# SIM3L164_C register map
File version: 1
CPU: 
Registers are 32-bit, read-write, reset 0x0 unless marked. A register's access mark holds for its fields unless they carry their own. Offsets are from the block's base; [hi:lo] are bit positions; {n}, {i} and the like mark numbered series.

## EXTOSC_0
Base 0x4003C000
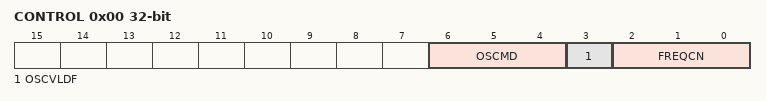
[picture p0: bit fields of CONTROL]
0x00 CONTROL — Oscillator Control
  [6:4] OSCMD — Oscillator Mode.
    0=OFF (External oscillator off.); 2=CMOS (External CMOS clock mode.); 3=CMOSDIV2 (External CMOS with divide by 2 stage.); 4=RC (RC oscillator mode with divide by 2 stage.); 5=C (C oscillator mode with divide by 2 stage.); 6=XTAL (Crystal oscillator mode.); 7=XTALDIV2 (Crystal oscillator mode with divide by 2 stage.)
  [3] OSCVLDF ro — Oscillator Valid Flag.
    0=NOT_SET (The external oscillator is unused or not yet stable.); 1=SET (The external oscillator is running and stable.)
  [2:0] FREQCN — Frequency Control.
    {v}=RANGE{v} (Set the external oscillator to range {v}.) (v=0..7)

## PVTOSC_0
Base 0x4003D000
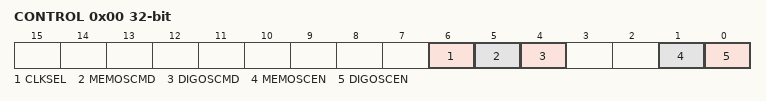
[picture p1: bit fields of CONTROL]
0x00 CONTROL — Module Control
  [6] CLKSEL — Clock Select.
    0=OSCILLATORS (Select the digital and memory oscillators as the inputs to the clock dividers.); 1=AHB (Select the APB clock as the input to the clock dividers.)
  [5] MEMOSCMD — High Voltage Oscillator Mode.
    0=FAST (Select fast mode for the memory LDO PVT oscillator.); 1=SLOW (Select slow mode for the memory LDO PVT oscillator.)
  [4] DIGOSCMD — Digital LDO Oscillator Mode.
    0=FAST (Select fast mode for the digital LDO PVT oscillator.); 1=SLOW (Select slow mode for the digital LDO PVT oscillator.)
  [1] MEMOSCEN — Memory LDO Oscillator Enable.
    0=DISABLED (Disable the memory LDO PVT oscillator.); 1=ENABLED (Enable the memory LDO PVT oscillator.)
  [0] DIGOSCEN — Digital LDO Oscillator Enable.
    0=DISABLED (Disable the digital LDO PVT oscillator.); 1=ENABLED (Enable the digital LDO PVT oscillator.)

## PBGP_4
Base 0x4002A320
0x00 PB reset 0xFFFF — Output Latch
  [15:0] PB — Output Latch.
0x10 PBPIN — Pin Value
  [15:0] PBPIN ro — Pin Value.
0x20 PBMDSEL reset 0xFFFF — Mode Select
  [15:0] PBMDSEL — Mode Select.
0x30 PBOUTMD — Output Mode
  [15:0] PBOUTMD — Output Mode.
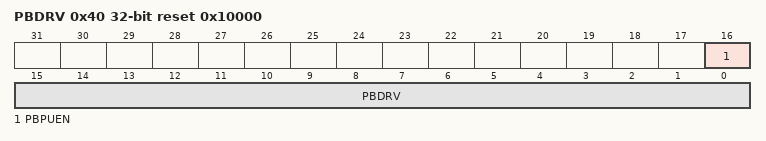
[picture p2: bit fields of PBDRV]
0x40 PBDRV reset 0x10000 — Drive Strength
  [16] PBPUEN — Port Bank Weak Pull-up Enable.
    0=DISABLED (Disable weak pull-ups for this port.); 1=ENABLED (Enable weak pull-ups for this port.)
  [15:0] PBDRV — Drive Strength.
0x50 PM — Port Match Value
  [15:0] PM — Port Match Value.
0x60 PMEN — Port Match Enable
  [15:0] PMEN — Port Match Enable.

## PBSTD_0
Base 0x4002A0A0
0x00 PB reset 0xFFFF — Output Latch
  [15:0] PB — Output Latch.
0x10 PBPIN — Pin Value
  [15:0] PBPIN ro — Pin Value.
0x20 PBMDSEL reset 0xFFFF — Mode Select
  [15:0] PBMDSEL — Mode Select.
0x30 PBSKIPEN — Crossbar Pin Skip Enable
  [15:0] PBSKIPEN — Crossbar Pin Skip Enable.
0x40 PBOUTMD — Output Mode
  [15:0] PBOUTMD — Output Mode.
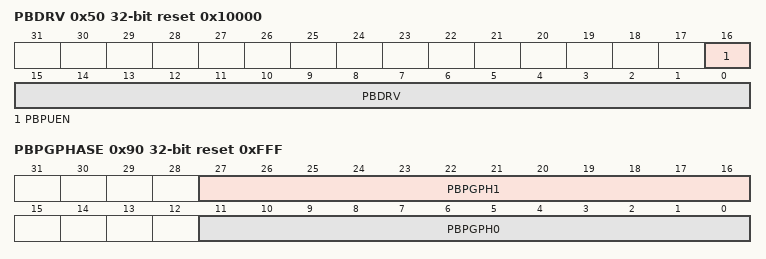
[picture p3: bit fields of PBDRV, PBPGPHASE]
0x50 PBDRV reset 0x10000 — Drive Strength
  [16] PBPUEN — Port Bank Weak Pull-up Enable.
    0=DISABLED (Disable weak pull-ups for this port.); 1=ENABLED (Enable weak pull-ups for this port.)
  [15:0] PBDRV — Drive Strength.
0x60 PM — Port Match Value
  [15:0] PM — Port Match Value.
0x70 PMEN — Port Match Enable
  [15:0] PMEN — Port Match Enable.
0x80 PBPGEN — Pulse Generator Pin Enable
  [11:0] PBPGEN — Pulse Generator Pin Enable.
0x90 PBPGPHASE reset 0xFFF — Pulse Generator Phase
  [27:16] PBPGPH1 — Pulse Generator Phase 1.
  [11:0] PBPGPH0 — Pulse Generator Phase 0.

## PBSTD_1
Base 0x4002A140
Registers as PBSTD_0, without PBPGEN, PBPGPHASE.

## PBSTD_2
Base 0x4002A1E0
Registers as PBSTD_0, without PBPGEN, PBPGPHASE.

## PBSTD_3
Base 0x4002A280
Registers as PBSTD_0, without PBPGEN, PBPGPHASE.

## SCONFIG_0
Base 0x400490B0
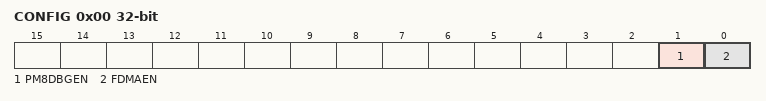
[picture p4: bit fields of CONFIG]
0x00 CONFIG — System Configuration
  [1] PM8DBGEN — Power Mode 8 Debug Enable.
    0=DISABLED (Disable debugging through Power Mode 8.); 1=ENABLED (Enable debugging through Power Mode 8. Power measurements cannot be made with debugging enabled.)
  [0] FDMAEN — Faster DMA Mode Enable.
    0=DISABLED (Disable the faster DMA mode. The DMA module and channels will behave like a standard uDMA.); 1=ENABLED (Enable the faster DMA mode.)

## VMON_0
Base 0x4002F000
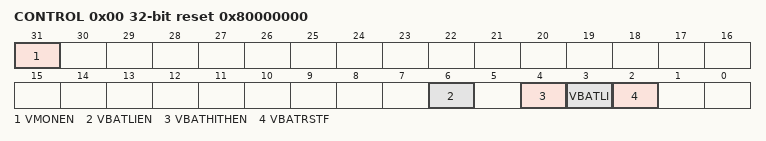
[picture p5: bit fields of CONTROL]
0x00 CONTROL reset 0x80000000 — Module Control
  [31] VMONEN — VBAT Supply Monitor Enable.
    0=DISABLED (Disable the VBAT supply monitor.); 1=ENABLED (Enable the VBAT supply monitor.)
  [6] VBATLIEN — VBAT Low Interrupt Enable.
    0=DISABLED (Disable the VBAT low interrupt.); 1=ENABLED (Enable the VBAT low interrupt.)
  [4] VBATHITHEN — VBAT High Threshold Enable.
    0=DISABLED (Use the standard VBAT thresholds.); 1=ENABLED (Use the high VBAT thresholds.)
  [3] VBATLI ro — VBAT Low Interrupt Flag.
    0=VBAT_IS_LOW (The VBAT voltage is below the early warning threshold.); 1=VBAT_IS_OK (The VBAT voltage is above the early warning threshold.)
  [2] VBATRSTF ro — VBAT Reset Threshold Status Flag.
    0=VBAT_IS_BELOW_RESET (The VBAT voltage is below the VBAT reset threshold.); 1=VBAT_IS_ABOVE_RESET (The VBAT voltage is above the VBAT reset threshold.)

## VREF_0
Base 0x40039010
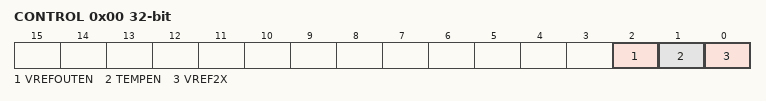
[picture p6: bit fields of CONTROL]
0x00 CONTROL — Module Control
  [2] VREFOUTEN — VREF Output Enable.
    0=DISABLED (Internal VREF is not driven on the VREF pin.); 1=ENABLED (Internal VREF is driven out to the VREF pin.)
  [1] TEMPEN — Temperature Sensor Enable.
    0=DISABLED (Disable the temperature sensor.); 1=ENABLED (Enable the temperature sensor.)
  [0] VREF2X — Voltage Reference Doubler.
    0=DISABLED (VREF output is nominally 1.2 V); 1=ENABLED (VREF output is nominally 2.4 V)

## WDTIMER_0
Base 0x40030000
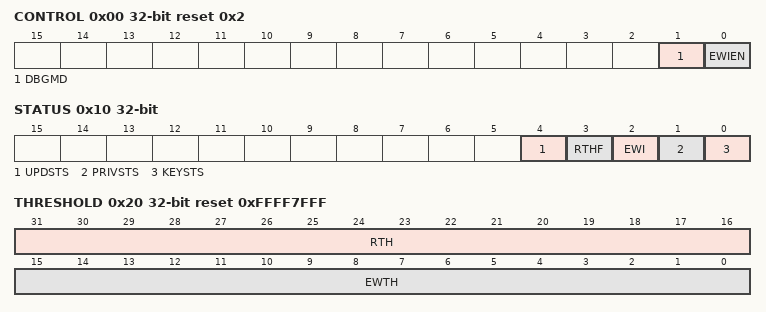
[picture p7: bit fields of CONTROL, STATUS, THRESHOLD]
0x00 CONTROL reset 0x2 — Module Control
  [1] DBGMD — Watchdog Timer Debug Mode.
    0=RUN (The WDTIMER module will continue to operate while the core is halted in debug mode.); 1=HALT (A debug breakpoint will cause the WDTIMER module to halt.)
  [0] EWIEN — Early Warning Interrupt Enable.
    0=DISABLED (Disable the early warning interrupt (EWI).); 1=ENABLED (Enable the early warning interrupt (EWI).)
0x10 STATUS — Module Status
  [4] UPDSTS ro — Watchdog Timer Threshold Update Status.
    0=IDLE (An update completed or is not pending. The EWTH and RTH fields can be written.); 1=UPDATING (An update of the threshold register is occurring. The EWTH and RTH fields should not be modified until hardware clears UPDSTS to 0.)
  [3] RTHF ro — Reset Threshold Flag.
    0=LT (The counter is currently less than the reset threshold (RTH) value.); 1=GTE (The counter is currently greater than or equal to the reset threshold (RTH) value.)
  [2] EWI — Early Warning Interrupt Flag.
    0=NOT_SET (Read: An early warning match did not occur. Write: Clear the early warning interrupt.); 1=SET (Read: An early warning match occurred and the interrupt is pending. Write: Force a watchdog timer early warning interrupt to occur.)
  [1] PRIVSTS ro — Register Access Status.
    0=READ_ONLY (The watchdog timer registers are currently read-only.); 1=READ_WRITE (A write transaction can be performed on the module registers.)
  [0] KEYSTS ro — Key Status.
    0=IDLE (No keys have been processed by the interface.); 1=READY (The attention key has been received and the module is awaiting a command.)
0x20 THRESHOLD reset 0xFFFF7FFF — Threshold Values
  [31:16] RTH — Reset Threshold.
  [15:0] EWTH — Early Warning Threshold.
0x30 WDTKEY — Module Key
  [7:0] KEY wo — Watchdog Timer Key.
    165=ATTN (Attention key to start the command sequence.); 204=RESET (Reset the watchdog timer.); 221=DISABLE (Disable the watchdog timer.); 238=START (Start the watchdog timer.); 241=WRITE (Allow one write access to the module registers.); 255=LOCK (Lock the module from any other writes until the next system reset.)
